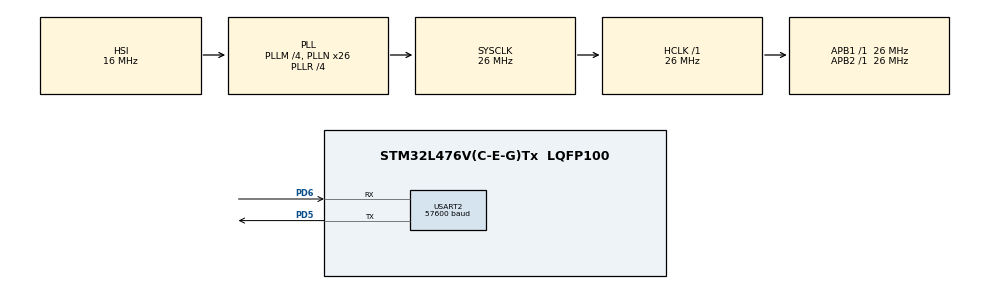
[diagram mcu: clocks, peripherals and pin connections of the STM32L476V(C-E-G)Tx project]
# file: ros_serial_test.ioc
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Dma.Request0=USART2_RX
Dma.Request1=USART2_TX
Dma.USART2_RX.0.Direction=DMA_PERIPH_TO_MEMORY
Dma.USART2_RX.0.Instance=DMA1_Channel6
Dma.USART2_RX.0.MemDataAlignment=DMA_MDATAALIGN_BYTE
Dma.USART2_RX.0.MemInc=DMA_MINC_ENABLE
Dma.USART2_RX.0.Mode=DMA_NORMAL
Dma.USART2_RX.0.PeriphDataAlignment=DMA_PDATAALIGN_BYTE
Dma.USART2_RX.0.PeriphInc=DMA_PINC_DISABLE
Dma.USART2_RX.0.Priority=DMA_PRIORITY_LOW
Dma.USART2_TX.1.Direction=DMA_MEMORY_TO_PERIPH
Dma.USART2_TX.1.Instance=DMA1_Channel7
Dma.USART2_TX.1.MemDataAlignment=DMA_MDATAALIGN_BYTE
Dma.USART2_TX.1.MemInc=DMA_MINC_ENABLE
Dma.USART2_TX.1.Mode=DMA_NORMAL
Dma.USART2_TX.1.PeriphDataAlignment=DMA_PDATAALIGN_BYTE
Dma.USART2_TX.1.PeriphInc=DMA_PINC_DISABLE
Dma.USART2_TX.1.Priority=DMA_PRIORITY_LOW
Mcu.Family=STM32L4
Mcu.Name=STM32L476V(C-E-G)Tx
Mcu.Package=LQFP100
NVIC.DMA1_Channel6_IRQn=true\:0\:0\:false\:false\:true\:false\:true\:true
NVIC.DMA1_Channel7_IRQn=true\:0\:0\:false\:false\:true\:false\:true\:true
NVIC.PriorityGroup=NVIC_PRIORITYGROUP_4
NVIC.USART2_IRQn=true\:0\:0\:false\:false\:true\:true\:true\:true
PC14-OSC32_IN\ (PC14).Mode=LSE-External-Oscillator
PC14-OSC32_IN\ (PC14).Signal=RCC_OSC32_IN
PC15-OSC32_OUT\ (PC15).Mode=LSE-External-Oscillator
PC15-OSC32_OUT\ (PC15).Signal=RCC_OSC32_OUT
PD5.Mode=Asynchronous
PD5.Signal=USART2_TX
PD6.Mode=Asynchronous
PD6.Signal=USART2_RX
PH0-OSC_IN\ (PH0).Mode=HSE-External-Clock-Source
PH0-OSC_IN\ (PH0).Signal=RCC_OSC_IN
ProjectManager.HeapSize=0x200
ProjectManager.StackSize=0x400
ProjectManager.TargetToolchain=STM32CubeIDE
RCC.ADCFreq_Value=16000000
RCC.AHBFreq_Value=26000000
RCC.APB1Freq_Value=26000000
RCC.APB1TimFreq_Value=26000000
RCC.APB2Freq_Value=26000000
RCC.APB2TimFreq_Value=26000000
RCC.CortexFreq_Value=26000000
RCC.FLatency=FLASH_LATENCY_4
RCC.HCLKFreq_Value=26000000
RCC.HSE_VALUE=8000000
RCC.HSI_VALUE=16000000
RCC.MSIAutoCalibration=DISABLED
RCC.MSI_VALUE=4000000
RCC.PLLM=4
RCC.PLLN=26
RCC.PLLR=RCC_PLLR_DIV4
RCC.PLLSourceVirtual=RCC_PLLSOURCE_HSI
RCC.PREFETCH_ENABLE=1
RCC.PWR_Regulator_Voltage_Scale=PWR_REGULATOR_VOLTAGE_SCALE2
RCC.SYSCLKFreq_VALUE=26000000
RCC.SYSCLKSource=RCC_SYSCLKSOURCE_PLLCLK
RCC.USBFreq_Value=16000000
RCC.VCOOutputFreq_Value=104000000
USART2.BaudRate=57600
USART2.VirtualMode-Asynchronous=VM_ASYNC
USART2.WordLength=WORDLENGTH_8B
board=custom

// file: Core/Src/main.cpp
/* USER CODE BEGIN Header */
/**
  ******************************************************************************
  * @file           : main.c
  * @brief          : Main program body
  ******************************************************************************
  * @attention
  *
  * Copyright (c) 2024 STMicroelectronics.
  * All rights reserved.
  *
  * This software is licensed under terms that can be found in the LICENSE file
  * in the root directory of this software component.
  * If no LICENSE file comes with this software, it is provided AS-IS.
  *
  ******************************************************************************
  */
/* USER CODE END Header */
#include "main.h"
#include "dma.h"
#include "usart.h"
#include "gpio.h"

/* USER CODE BEGIN Includes */
#include "mainpp.h"
/* USER CODE END Includes */

void SystemClock_Config(void);

int main(void)
{

  /* MCU Configuration--------------------------------------------------------*/

  /* Reset of all peripherals, Initializes the Flash interface and the Systick. */
  HAL_Init();

  /* Configure the system clock */
  SystemClock_Config();

  /* Initialize all configured peripherals */
  MX_GPIO_Init();
  MX_DMA_Init();
  MX_USART2_UART_Init();
  /* USER CODE BEGIN 2 */
  setup(); // from ros serial example
  /* USER CODE END 2 */

  /* Infinite loop */
  while (1)
  {

    /* USER CODE BEGIN 3 */
		loop(); // from ros serial example
  }
  /* USER CODE END 3 */
}

void SystemClock_Config(void)
{
  RCC_OscInitTypeDef RCC_OscInitStruct = {0};
  RCC_ClkInitTypeDef RCC_ClkInitStruct = {0};

  /** Configure the main internal regulator output voltage
  */
  if (HAL_PWREx_ControlVoltageScaling(PWR_REGULATOR_VOLTAGE_SCALE2) != HAL_OK)
  {
    Error_Handler();
  }

  /** Initializes the RCC Oscillators according to the specified parameters
  * in the RCC_OscInitTypeDef structure.
  */
  RCC_OscInitStruct.OscillatorType = RCC_OSCILLATORTYPE_HSI;
  RCC_OscInitStruct.HSIState = RCC_HSI_ON;
  RCC_OscInitStruct.HSICalibrationValue = RCC_HSICALIBRATION_DEFAULT;
  RCC_OscInitStruct.PLL.PLLState = RCC_PLL_ON;
  RCC_OscInitStruct.PLL.PLLSource = RCC_PLLSOURCE_HSI;
  RCC_OscInitStruct.PLL.PLLM = 4;
  RCC_OscInitStruct.PLL.PLLN = 26;
  RCC_OscInitStruct.PLL.PLLP = RCC_PLLP_DIV7;
  RCC_OscInitStruct.PLL.PLLQ = RCC_PLLQ_DIV2;
  RCC_OscInitStruct.PLL.PLLR = RCC_PLLR_DIV4;
  if (HAL_RCC_OscConfig(&RCC_OscInitStruct) != HAL_OK)
  {
    Error_Handler();
  }

  /** Initializes the CPU, AHB and APB buses clocks
  */
  RCC_ClkInitStruct.ClockType = RCC_CLOCKTYPE_HCLK|RCC_CLOCKTYPE_SYSCLK
                              |RCC_CLOCKTYPE_PCLK1|RCC_CLOCKTYPE_PCLK2;
  RCC_ClkInitStruct.SYSCLKSource = RCC_SYSCLKSOURCE_PLLCLK;
  RCC_ClkInitStruct.AHBCLKDivider = RCC_SYSCLK_DIV1;
  RCC_ClkInitStruct.APB1CLKDivider = RCC_HCLK_DIV1;
  RCC_ClkInitStruct.APB2CLKDivider = RCC_HCLK_DIV1;

  if (HAL_RCC_ClockConfig(&RCC_ClkInitStruct, FLASH_LATENCY_4) != HAL_OK)
  {
    Error_Handler();
  }
}

void Error_Handler(void)
{
  __disable_irq();
  while (1)
  {
  }
}
